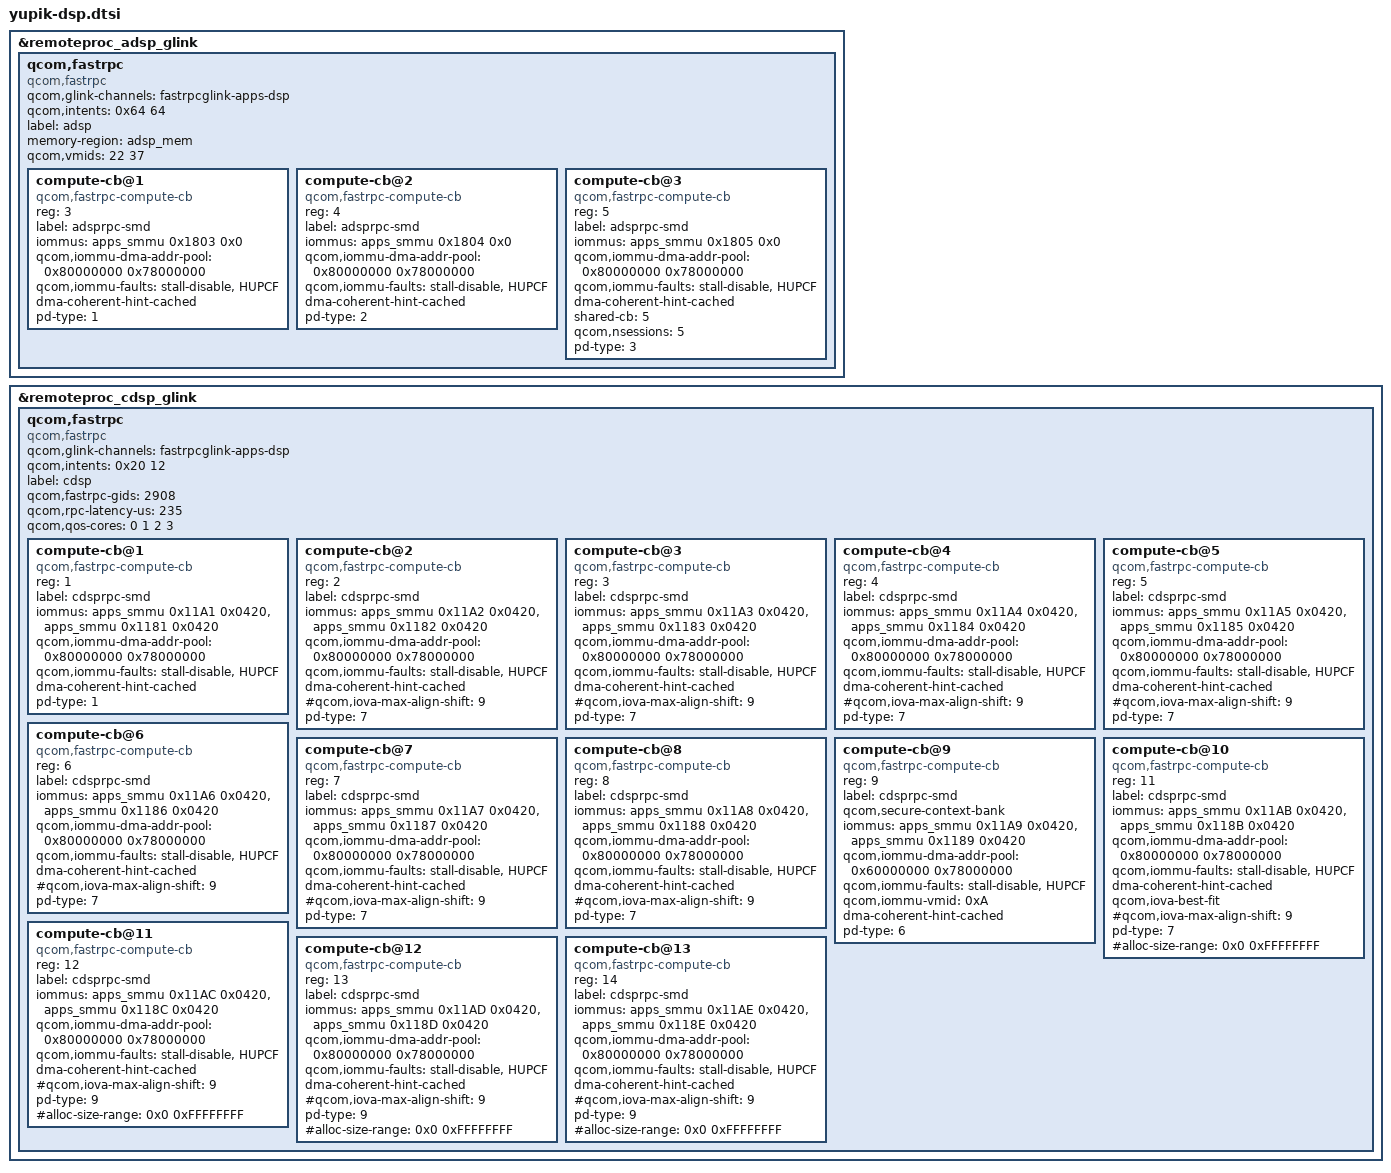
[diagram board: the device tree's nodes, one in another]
// SPDX-License-Identifier: BSD-3-Clause
/*
 * Copyright (c) Qualcomm Technologies, Inc. and/or its subsidiaries.
 */
&remoteproc_adsp_glink {
	qcom,fastrpc {
		compatible = "qcom,fastrpc";
		qcom,glink-channels = "fastrpcglink-apps-dsp";
		qcom,intents = <0x64 64>;
		label = "adsp";
		memory-region = <&adsp_mem>;
		qcom,vmids  = <22 37>;


		compute-cb@1 {
			compatible = "qcom,fastrpc-compute-cb";
			reg = <3>;
			label = "adsprpc-smd";
			iommus = <&apps_smmu 0x1803 0x0>;
			qcom,iommu-dma-addr-pool = <0x80000000 0x78000000>;
			qcom,iommu-faults = "stall-disable" , "HUPCF";
			dma-coherent-hint-cached;
			pd-type = <1>;
		};

		compute-cb@2 {
			compatible = "qcom,fastrpc-compute-cb";
			reg = <4>;
			label = "adsprpc-smd";
			iommus = <&apps_smmu 0x1804 0x0>;
			qcom,iommu-dma-addr-pool = <0x80000000 0x78000000>;
			qcom,iommu-faults = "stall-disable" , "HUPCF";
			dma-coherent-hint-cached;
                        pd-type = <2>;
		};
		compute-cb@3 {
			compatible = "qcom,fastrpc-compute-cb";
			reg = <5>;
			label = "adsprpc-smd";
			iommus = <&apps_smmu 0x1805 0x0>;
			qcom,iommu-dma-addr-pool = <0x80000000 0x78000000>;
			qcom,iommu-faults = "stall-disable" , "HUPCF";
			dma-coherent-hint-cached;
			shared-cb = <5>;
            qcom,nsessions = <5>;
			pd-type = <3>;
		};
	};
};


&remoteproc_cdsp_glink {
	qcom,fastrpc {
		compatible = "qcom,fastrpc";
		//qcom,glink-channels = "cdsprmglink-apps-dsp";
		qcom,glink-channels = "fastrpcglink-apps-dsp";
		qcom,intents = <0x20 12>;
		label = "cdsp";
		qcom,fastrpc-gids = <2908>;
		qcom,rpc-latency-us = <235>;
                qcom,qos-cores = <0 1 2 3>;

		compute-cb@1 {
			compatible = "qcom,fastrpc-compute-cb";
			reg = <1>;
			label = "cdsprpc-smd";
			iommus = <&apps_smmu 0x11A1 0x0420>,
					<&apps_smmu 0x1181 0x0420>;
			qcom,iommu-dma-addr-pool = <0x80000000 0x78000000>;
			qcom,iommu-faults = "stall-disable" , "HUPCF";
			dma-coherent-hint-cached;
			pd-type = <1>;
		};

		compute-cb@2 {
			compatible = "qcom,fastrpc-compute-cb";
			reg = <2>;
			label = "cdsprpc-smd";
			iommus = <&apps_smmu 0x11A2 0x0420>,
					<&apps_smmu 0x1182 0x0420>;
			qcom,iommu-dma-addr-pool = <0x80000000 0x78000000>;
			qcom,iommu-faults = "stall-disable" , "HUPCF";
			dma-coherent-hint-cached;
			#qcom,iova-max-align-shift = <9>;
			pd-type = <7>;
		};

		compute-cb@3 {
			compatible = "qcom,fastrpc-compute-cb";
			reg = <3>;
			label = "cdsprpc-smd";
			iommus = <&apps_smmu 0x11A3 0x0420>,
					<&apps_smmu 0x1183 0x0420>;
			qcom,iommu-dma-addr-pool = <0x80000000 0x78000000>;
			qcom,iommu-faults = "stall-disable" , "HUPCF";
			dma-coherent-hint-cached;

			#qcom,iova-max-align-shift = <9>;
			pd-type = <7>;
		};

		compute-cb@4 {
			compatible = "qcom,fastrpc-compute-cb";
			reg = <4>;
			label = "cdsprpc-smd";
			iommus = <&apps_smmu 0x11A4 0x0420>,
					<&apps_smmu 0x1184 0x0420>;
			qcom,iommu-dma-addr-pool = <0x80000000 0x78000000>;
			qcom,iommu-faults = "stall-disable" , "HUPCF";
			dma-coherent-hint-cached;

			#qcom,iova-max-align-shift = <9>;
			pd-type = <7>;
		};

		compute-cb@5 {
			compatible = "qcom,fastrpc-compute-cb";
			reg = <5>;
			label = "cdsprpc-smd";
			iommus = <&apps_smmu 0x11A5 0x0420>,
					<&apps_smmu 0x1185 0x0420>;
			qcom,iommu-dma-addr-pool = <0x80000000 0x78000000>;
			qcom,iommu-faults = "stall-disable" , "HUPCF";
			dma-coherent-hint-cached;

			#qcom,iova-max-align-shift = <9>;
			pd-type = <7>;
		};

		compute-cb@6 {
			compatible = "qcom,fastrpc-compute-cb";
			reg = <6>;
			label = "cdsprpc-smd";
			iommus = <&apps_smmu 0x11A6 0x0420>,
					<&apps_smmu 0x1186 0x0420>;
			qcom,iommu-dma-addr-pool = <0x80000000 0x78000000>;
			qcom,iommu-faults = "stall-disable" , "HUPCF";
			dma-coherent-hint-cached;

			#qcom,iova-max-align-shift = <9>;
			pd-type = <7>;
		};

		compute-cb@7 {
			compatible = "qcom,fastrpc-compute-cb";
			reg = <7>;
			label = "cdsprpc-smd";
			iommus = <&apps_smmu 0x11A7 0x0420>,
					<&apps_smmu 0x1187 0x0420>;
			qcom,iommu-dma-addr-pool = <0x80000000 0x78000000>;
			qcom,iommu-faults = "stall-disable" , "HUPCF";
			dma-coherent-hint-cached;

			#qcom,iova-max-align-shift = <9>;
			pd-type = <7>;
		};

		compute-cb@8 {
			compatible = "qcom,fastrpc-compute-cb";
			reg = <8>;
			label = "cdsprpc-smd";
			iommus = <&apps_smmu 0x11A8 0x0420>,
					<&apps_smmu 0x1188 0x0420>;
			qcom,iommu-dma-addr-pool = <0x80000000 0x78000000>;
			qcom,iommu-faults = "stall-disable" , "HUPCF";
			dma-coherent-hint-cached;

			#qcom,iova-max-align-shift = <9>;
			pd-type = <7>;
		};

		compute-cb@9 {
			compatible = "qcom,fastrpc-compute-cb";
			reg = <9>;
			label = "cdsprpc-smd";
			qcom,secure-context-bank;
			iommus = <&apps_smmu 0x11A9 0x0420>,
					<&apps_smmu 0x1189 0x0420>;
			qcom,iommu-dma-addr-pool = <0x60000000 0x78000000>;
			qcom,iommu-faults = "stall-disable" , "HUPCF";
			qcom,iommu-vmid = <0xA>;
			dma-coherent-hint-cached;
			pd-type = <6>;
		};

		compute-cb@10 {
			compatible = "qcom,fastrpc-compute-cb";
			reg = <11>;
			label = "cdsprpc-smd";
			iommus = <&apps_smmu 0x11AB 0x0420>,
					<&apps_smmu 0x118B 0x0420>;
			qcom,iommu-dma-addr-pool = <0x80000000 0x78000000>;
			qcom,iommu-faults = "stall-disable" , "HUPCF";
			dma-coherent-hint-cached;
         		qcom,iova-best-fit;
			#qcom,iova-max-align-shift = <9>;
			pd-type = <7>;
			#alloc-size-range = <0x0 0xFFFFFFFF>;
		};

		compute-cb@11 {
			compatible = "qcom,fastrpc-compute-cb";
			reg = <12>;
			label = "cdsprpc-smd";
			iommus = <&apps_smmu 0x11AC 0x0420>,
					<&apps_smmu 0x118C 0x0420>;
			qcom,iommu-dma-addr-pool = <0x80000000 0x78000000>;
			qcom,iommu-faults = "stall-disable" , "HUPCF";
			dma-coherent-hint-cached;

			#qcom,iova-max-align-shift = <9>;
			pd-type = <9>;
			#alloc-size-range = <0x0 0xFFFFFFFF>;
		};

		compute-cb@12 {
			compatible = "qcom,fastrpc-compute-cb";
			reg = <13>;
			label = "cdsprpc-smd";
			iommus = <&apps_smmu 0x11AD 0x0420>,
					<&apps_smmu 0x118D 0x0420>;
			qcom,iommu-dma-addr-pool = <0x80000000 0x78000000>;
			qcom,iommu-faults = "stall-disable" , "HUPCF";
			dma-coherent-hint-cached;

			#qcom,iova-max-align-shift = <9>;
			pd-type = <9>;
			#alloc-size-range = <0x0 0xFFFFFFFF>;
		};

		compute-cb@13 {
			compatible = "qcom,fastrpc-compute-cb";
			reg = <14>;
			label = "cdsprpc-smd";
			iommus = <&apps_smmu 0x11AE 0x0420>,
					<&apps_smmu 0x118E 0x0420>;
			qcom,iommu-dma-addr-pool = <0x80000000 0x78000000>;
			qcom,iommu-faults = "stall-disable" , "HUPCF";
			dma-coherent-hint-cached;

			#qcom,iova-max-align-shift = <9>;
			pd-type = <9>;
			#alloc-size-range = <0x0 0xFFFFFFFF>;
		};
	};
};
